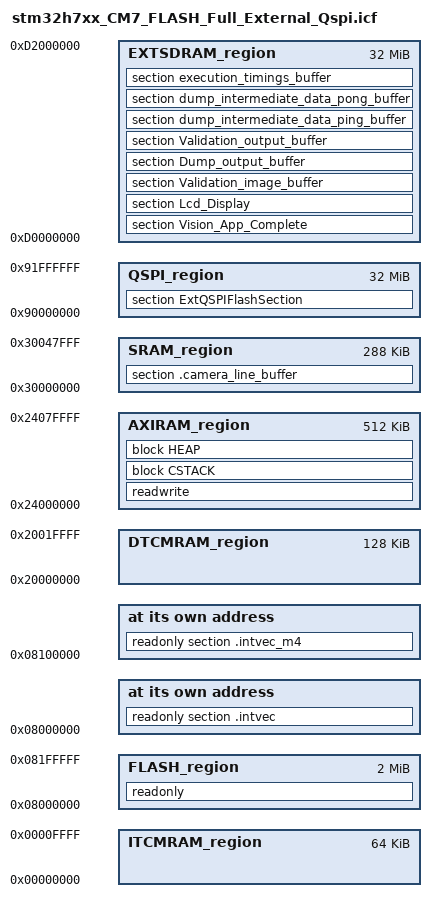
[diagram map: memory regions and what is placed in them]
/*###ICF### Section handled by ICF editor, don't touch! ****/
/*-Editor annotation file-*/
/* IcfEditorFile="$TOOLKIT_DIR$\config\ide\IcfEditor\cortex_v1_0.xml" */

/*-Specials-*/
define symbol __ICFEDIT_intvec_start__ = 0x08000000;
define symbol __ICFEDIT_intvec_start_m4__ = 0x08100000;

/*-Memory Regions-*/
define symbol __ICFEDIT_region_FLASH_start__     = 0x08000000;
define symbol __ICFEDIT_region_FLASH_end__       = 0x081FFFFF;
define symbol __ICFEDIT_region_AXISRAM_start__   = 0x24000000;
define symbol __ICFEDIT_region_AXISRAM_end__      = 0x2407FFFF;
define symbol __ICFEDIT_region_SRAM_start__      = 0x30000000;
define symbol __ICFEDIT_region_SRAM_end__       = 0x30047FFF;
define symbol __ICFEDIT_region_DTCMRAM_start__ = 0x20000000;
define symbol __ICFEDIT_region_DTCMRAM_end__   = 0x2001FFFF;
define symbol __ICFEDIT_region_ITCMRAM_start__ = 0x00000000;
define symbol __ICFEDIT_region_ITCMRAM_end__   = 0x0000FFFF;
define symbol __ICFEDIT_region_EXTSDRAM_start__ = 0xD0000000;
define symbol __ICFEDIT_region_EXTSDRAM_end__   = 0xD2000000;
define symbol __ICFEDIT_region_QSPI_start__     = 0x90000000;
define symbol __ICFEDIT_region_QSPI_end__       = 0x91FFFFFF;

/*-Sizes-*/
define symbol __ICFEDIT_size_cstack__ = 0x1000;
define symbol __ICFEDIT_size_heap__   = 0x500;
/**** End of ICF editor section. ###ICF###*/

define memory mem with size = 4G;
define region FLASH_region      = mem:[from __ICFEDIT_region_FLASH_start__   to __ICFEDIT_region_FLASH_end__];
define region AXIRAM_region      = mem:[from __ICFEDIT_region_AXISRAM_start__   to __ICFEDIT_region_AXISRAM_end__];
define region SRAM_region      = mem:[from __ICFEDIT_region_SRAM_start__   to __ICFEDIT_region_SRAM_end__];
define region DTCMRAM_region  = mem:[from __ICFEDIT_region_DTCMRAM_start__ to __ICFEDIT_region_DTCMRAM_end__];
define region ITCMRAM_region  = mem:[from __ICFEDIT_region_ITCMRAM_start__ to __ICFEDIT_region_ITCMRAM_end__];
define region EXTSDRAM_region  = mem:[from __ICFEDIT_region_EXTSDRAM_start__ to __ICFEDIT_region_EXTSDRAM_end__];
define region QSPI_region  = mem:[from __ICFEDIT_region_QSPI_start__ to __ICFEDIT_region_QSPI_end__];

define block CSTACK    with alignment = 8, size = __ICFEDIT_size_cstack__   { };
define block HEAP      with alignment = 8, size = __ICFEDIT_size_heap__     { };

initialize by copy { readwrite };
do not initialize  { section .noinit };

place at address mem:__ICFEDIT_intvec_start__ { readonly section .intvec };
place at address mem:__ICFEDIT_intvec_start_m4__ { readonly section .intvec_m4 };

export symbol __ICFEDIT_size_cstack__;
place in FLASH_region   { readonly };
place in AXIRAM_region  { readwrite, block CSTACK, block HEAP };
place in SRAM_region     { section .camera_line_buffer };
place in EXTSDRAM_region { section Vision_App_Complete, section Lcd_Display, section Validation_image_buffer, section Dump_output_buffer, section Validation_output_buffer, section dump_intermediate_data_ping_buffer, section dump_intermediate_data_pong_buffer, section execution_timings_buffer };
place in QSPI_region { section ExtQSPIFlashSection };


                                   
                                   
